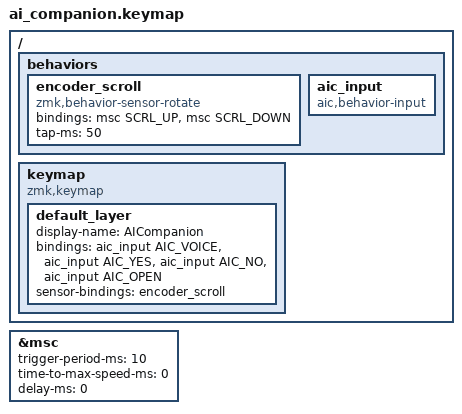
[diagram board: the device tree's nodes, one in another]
/*
 * Copyright (c) 2026 The AI Companion Contributors
 * SPDX-License-Identifier: MIT
 *
 * ai_companion keymap.
 *
 * Encoder rotation = REAL function: mouse-wheel scroll (scroll the focused
 * window on the Mac, e.g. the Optimus session window). This is a generic HID
 * scroll, handled natively by macOS — no host app required.
 *   Encoder turn -> right = Scroll Up, left = Scroll Down
 *
 * The 4 buttons report their press to the Mac as an `input` message over the
 * USB CDC-ACM channel (Phase 5): each is bound to `&aic_input <KEY>` and the
 * host decides what the press means for the screen currently shown
 * (docs/phase5-interface-contract.md §5.1). They no longer type keycodes.
 *   Voice -> VOICE,  Yes -> YES,  No -> NO,  Open -> OPEN
 *
 * The DRV2605L haptic motor is HW-verified (2026-09-28); it is driven by host
 * commands in Phase 5, not by a physical button. The `&haptic` behavior stays
 * defined in the devicetree (node drv2605@5a) for host control.
 *
 * The rotary encoder is a 4-pin module (SIGA/SIGB/VCC/GND) whose push switch is
 * not routed to the header, so only rotation is used (no encoder-push button).
 *
 * How to verify: connect the Mac test tool (tools/aic_push.py) and press each
 * button -> an `input` line prints with the matching key. Turning the fitted
 * encoder scrolls the focused window.
 */

#include <behaviors.dtsi>
#include <dt-bindings/zmk/keys.h>

/*
 * Physical button ids passed to &aic_input. KEEP IN SYNC with the AIC_KEY_*
 * macros in src/aic_input.h.
 */
#define AIC_VOICE 0
#define AIC_YES   1
#define AIC_NO    2
#define AIC_OPEN  3

/*
 * Raise the default mouse-scroll speed BEFORE including pointing.h so SCRL_UP /
 * SCRL_DOWN carry a larger value. `&msc` (zmk,behavior-input-two-axis) is a
 * VELOCITY behavior: distance = speed x hold-time, accrued once per
 * trigger-period-ms tick. A sensor-rotate "tap" is far too short at the default
 * speed (10) so a detent scrolled ~0. See the &msc override + tap-ms below.
 */
#define ZMK_POINTING_DEFAULT_SCRL_VAL 60
#include <dt-bindings/zmk/pointing.h>

/ {
    behaviors {
        // Sensor-rotate behaviour: 1st binding = clockwise, 2nd = counter-clockwise.
        // Direction can be swapped after testing with the real encoder + macOS
        // "natural scrolling" setting.
        // tap-ms holds &msc long enough for several scroll ticks per detent:
        // ticks fire every trigger-period-ms (=10, overridden below), so a 50ms
        // hold ≈ 5 ticks; distance ≈ speed(60) x 10ms/1000 x 5 ≈ 3 wheel units.
        encoder_scroll: encoder_scroll {
            compatible = "zmk,behavior-sensor-rotate";
            #sensor-binding-cells = <0>;
            bindings = <&msc SCRL_UP>, <&msc SCRL_DOWN>;
            tap-ms = <50>;
        };

        // Physical-button behaviour: on press, report which button (the single
        // parameter, AIC_VOICE/YES/NO/OPEN) to the host as an `input` message.
        // Implemented in src/behavior_input.c (compatible "aic,behavior-input").
        aic_input: aic_input {
            compatible = "aic,behavior-input";
            #binding-cells = <1>;
        };
    };
};

/*
 * Make &msc react immediately and tick finely so a short per-detent hold still
 * produces a clean, perceptible scroll (defaults: trigger-period 16ms,
 * time-to-max-speed 300ms → a tap accrued nothing). acceleration-exponent is
 * already 0 (constant speed) in the stock node.
 */
&msc {
    trigger-period-ms = <10>;
    time-to-max-speed-ms = <0>;
    delay-ms = <0>;
};

/ {
    keymap {
        compatible = "zmk,keymap";

        default_layer {
            display-name = "AICompanion";
            bindings = <
                &aic_input AIC_VOICE   &aic_input AIC_YES   &aic_input AIC_NO   &aic_input AIC_OPEN
            >;
            // Encoder rotation = mouse-wheel scroll (real function: scroll the
            // focused Mac/Optimus window). Rotation hardware HW-verified 2026-09-28
            // via the volume-diagnostic build (turning changed macOS volume).
            sensor-bindings = <&encoder_scroll>;
        };
    };
};
